# STM32G031 register map
File version: 1.6
CPU: CM0 r0p1, little endian, MPU, no FPU, 2 interrupt priority bits
Registers are 32-bit, read-write, reset 0x0 unless marked. A register's access mark holds for its fields unless they carry their own. Offsets are from the block's base; [hi:lo] are bit positions; lines under a group give offsets from that group; {n}, {i} and the like mark numbered series; 'fields as' and 'values as' point back to an identical list.

## ADC — Analog to Digital Converter instance 1
Base 0x40012400
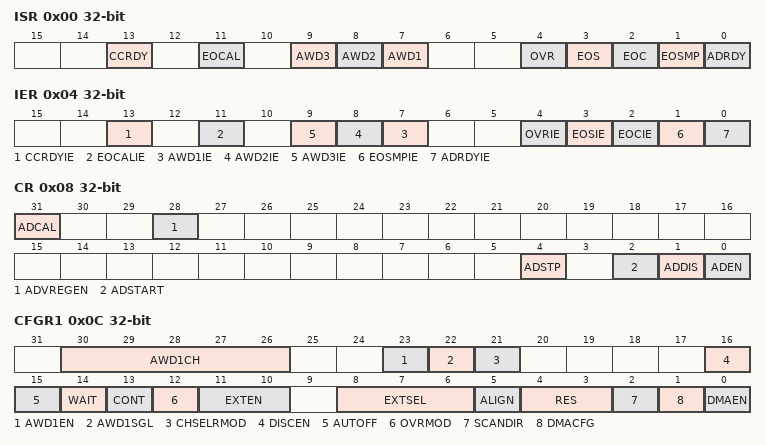
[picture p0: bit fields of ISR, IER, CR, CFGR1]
0x00 ISR — ADC interrupt and status register
  [13] CCRDY write-1-clears — Channel Configuration Ready flag
    on read: 0=NotComplete (Channel configuration update not applied); 1=Complete (Channel configuration update is applied) | on write: 1=Clear the channel configuration flag
  [11] EOCAL write-1-clears — End Of Calibration flag
    on read: 0=NotComplete (Calibration is not complete); 1=Complete (Calibration complete) | on write: 1=Clear the calibration flag
  [n+6] AWD{n} (n=1..3) write-1-clears — Analog watchdog {n} flag
    on read: 0=NoEvent (No analog watchdog event occurred); 1=Event (Analog watchdog event occurred) | on write: 1=Clear the analog watchdog event flag
  [4] OVR write-1-clears — ADC group regular overrun flag
    on read: 0=No overrun occurred; 1=Overrun occurred | on write: 1=Clear the overrun flag
  [3] EOS write-1-clears — ADC group regular end of sequence conversions flag
    on read: 0=NotComplete (Conversion sequence is not complete); 1=Complete (Conversion sequence complete) | on write: 1=Clear the conversion sequence flag
  [2] EOC write-1-clears — ADC group regular end of unitary conversion flag
    on read: 0=NotComplete (Channel conversion is not complete); 1=Complete (Channel conversion complete) | on write: 1=Clear the channel conversion flag
  [1] EOSMP write-1-clears — ADC group regular end of sampling flag
    on read: 0=NotAtEnd (Not at the end of the samplings phase); 1=AtEnd (End of sampling phase reached) | on write: 1=Clear the sampling phase flag
  [0] ADRDY write-1-clears — ADC ready flag
    on read: 0=NotReady (ADC not yet ready to start conversion); 1=Ready (ADC ready to start conversion) | on write: 1=Clear the ADC ready flag
0x04 IER — ADC interrupt enable register
  [13] CCRDYIE — Channel Configuration Ready Interrupt enable
    0=Disabled (Channel configuration ready interrupt disabled); 1=Enabled (Channel configuration ready interrupt enabled)
  [11] EOCALIE — End of calibration interrupt enable
    0=Disabled (End of calibration interrupt disabled); 1=Enabled (End of calibration interrupt enabled)
  [n+6] AWD{n}IE (n=1..3) — Analog watchdog {n} interrupt enable
    0=Disabled (Analog watchdog interrupt disabled); 1=Enabled (Analog watchdog interrupt enabled)
  [4] OVRIE — ADC group regular overrun interrupt
    0=Disabled (Overrun interrupt disabled); 1=Enabled (Overrun interrupt enabled. An interrupt is generated when the OVR bit is set.)
  [3] EOSIE — ADC group regular end of sequence conversions interrupt
    0=Disabled (EOS interrupt disabled); 1=Enabled (EOS interrupt enabled. An interrupt is generated when the EOS bit is set.)
  [2] EOCIE — ADC group regular end of unitary conversion interrupt
    0=Disabled (EOC interrupt disabled); 1=Enabled (EOC interrupt enabled. An interrupt is generated when the EOC bit is set.)
  [1] EOSMPIE — ADC group regular end of sampling interrupt
    0=Disabled (EOSMP interrupt disabled); 1=Enabled (EOSMP interrupt enabled. An interrupt is generated when the EOSMP bit is set.)
  [0] ADRDYIE — ADC ready interrupt
    0=Disabled (ADRDY interrupt disabled); 1=Enabled (ADRDY interrupt enabled. An interrupt is generated when the ADRDY bit is set.)
0x08 CR — ADC control register
  [31] ADCAL write-1-sets — ADC calibration
    on read: 0=NotCalibrating (ADC calibration either not yet performed or completed); 1=Calibrating (ADC calibration in progress) | on write: 1=StartCalibration (Start the ADC calibration sequence)
  [28] ADVREGEN — ADC voltage regulator enable
    0=Disabled (ADC voltage regulator disabled); 1=Enabled (ADC voltage regulator enabled)
  [4] ADSTP write-1-sets — ADC group regular conversion stop
    on read: 0=NotStopping (No stop command active); 1=Stopping (ADC stopping conversion) | on write: 1=StopConversion (Stop the active conversion)
  [2] ADSTART write-1-sets — ADC group regular conversion start
    on read: 0=NotActive (No conversion ongoing); 1=Active (ADC operating and may be converting) | on write: 1=StartConversion (Start the ADC conversion (may be delayed for hardware triggers))
  [1] ADDIS write-1-sets — ADC disable
    on read: 0=NotDisabling (No disable command active); 1=Disabling (ADC disabling) | on write: 1=Disable the ADC
  [0] ADEN write-1-sets — ADC enable
    on read: 0=Disabled (ADC disabled); 1=Enabled (ADC enabled) | on write: 1=Enabled (Enable the ADC)
0x0C CFGR1 — ADC configuration register 1
  [30:26] AWD1CH range 0..17 — ADC analog watchdog 1 monitored channel selection
  [23] AWD1EN — ADC analog watchdog 1 enable on scope ADC group regular
    0=Disabled (Analog watchdog 1 disabled); 1=Enabled (Analog watchdog 1 enabled)
  [22] AWD1SGL — ADC analog watchdog 1 monitoring a single channel or all channels
    0=AllChannels (Analog watchdog 1 enabled on all channels); 1=SingleChannel (Analog watchdog 1 enabled on a single channel)
  [21] CHSELRMOD — Mode selection of the ADC_CHSELR register
    0=BitPerInput (Each bit of the ADC_CHSELR register enables an input); 1=Sequence (ADC_CHSELR register is able to sequence up to 8 channels)
  [16] DISCEN — ADC group regular sequencer discontinuous mode
    0=Disabled (Discontinuous mode disabled); 1=Enabled (Discontinuous mode enabled)
  [15] AUTOFF — Auto-off mode
    0=Disabled (Auto-off mode disabled); 1=Enabled (Auto-off mode enabled)
  [14] WAIT — Wait conversion mode
    0=Disabled (Wait conversion mode off); 1=Enabled (Wait conversion mode on)
  [13] CONT — ADC group regular continuous conversion mode
    0=Single conversion mode; 1=Continuous conversion mode
  [12] OVRMOD — ADC group regular overrun configuration
    0=Preserve (ADC_DR register is preserved with the old data when an overrun is detected); 1=Overwrite (ADC_DR register is overwritten with the last conversion result when an overrun is detected)
  [11:10] EXTEN — ADC group regular external trigger polarity
    0=Disabled (Hardware trigger detection disabled); 1=RisingEdge (Hardware trigger detection on the rising edge); 2=FallingEdge (Hardware trigger detection on the falling edge); 3=BothEdges (Hardware trigger detection on both the rising and falling edges)
  [8:6] EXTSEL — ADC group regular external trigger source
    0=TIM1_TRGO2 (Timer 1 TRGO 2 event); 1=TIM1_CC4 (Timer 1 CC4 event); 2=TIM2_TRGO (Timer 2 TRGO event); 3=TIM3_TRGO (Timer 3 TRGO event); 4=TIM15_TRGO (Timer 15 TRGO event); 5=TIM6_TRGO (Timer 6 TRGO event); 6=TIM4_TRGO (Timer 4 TRGO event); 7=EXTI11 (EXTI line 11 event)
  [5] ALIGN — ADC data alignement
    0=Right alignment; 1=Left alignment
  [4:3] RES — ADC data resolution
    0=Bits12 (12 bits); 1=Bits10 (10 bits); 2=Bits8 (8 bits); 3=Bits6 (6 bits)
  [2] SCANDIR — Scan sequence direction
    0=Upward scan (from CHSEL0 to CHSEL17); 1=Backward scan (from CHSEL17 to CHSEL0)
  [1] DMACFG — ADC DMA transfer configuration
    0=OneShot (DMA one shot mode selected); 1=Circular (DMA circular mode selected)
  [0] DMAEN — ADC DMA transfer enable
    0=Disabled (DMA disabled); 1=Enabled (DMA enabled)
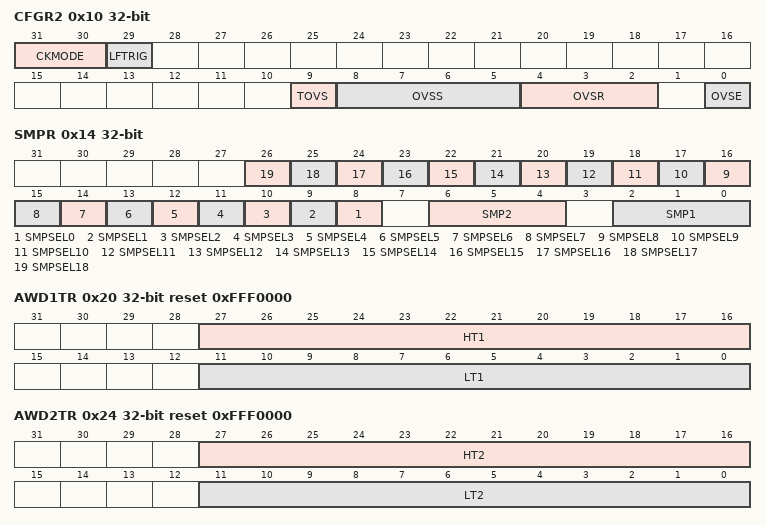
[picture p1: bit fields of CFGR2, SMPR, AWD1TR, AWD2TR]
0x10 CFGR2 — ADC configuration register 2
  [31:30] CKMODE — ADC clock mode
    0=ADCLK (ADCCLK (Asynchronous clock mode)); 1=PCLK_Div2 (PCLK/2 (Synchronous clock mode)); 2=PCLK_Div4 (PCLK/4 (Synchronous clock mode)); 3=PCLK (PCLK (Synchronous clock mode))
  [29] LFTRIG — Low frequency trigger mode enable
    0=Disabled (Low Frequency Trigger Mode disabled); 1=Enabled (Low Frequency Trigger Mode enabled)
  [9] TOVS — ADC oversampling discontinuous mode (triggered mode) for ADC group regular
    0=TriggerAll (All oversampled conversions for a channel are done consecutively after a trigger); 1=TriggerEach (Each oversampled conversion for a channel needs a trigger)
  [8:5] OVSS — ADC oversampling shift
    0=NoShift; 1=Shift 1-bit; {v}=Shift {v}-bits (v=2..8)
  [4:2] OVSR — ADC oversampling ratio
    0=Mul2 (2x); 1=Mul4 (4x); 2=Mul8 (8x); 3=Mul16 (16x); 4=Mul32 (32x); 5=Mul64 (64x); 6=Mul128 (128x); 7=Mul256 (256x)
  [0] OVSE — ADC oversampler enable on scope ADC group regular
    0=Disabled (Oversampler disabled); 1=Enabled (Oversampler enabled)
0x14 SMPR — ADC sampling time register
  [n+8] SMPSEL{n} (n=0..18) — Channel-{n} sampling time selection
    0=Smp1 (Sampling time of CHANNELx use the setting of SMP1 register); 1=Smp2 (Sampling time of CHANNELx use the setting of SMP2 register)
  [4n-2:4n-4] SMP{n} (n=1..2) — Sampling time selection {n}
    0=Cycles1_5 (1.5 ADC clock cycles); 1=Cycles3_5 (3.5 ADC clock cycles); 2=Cycles7_5 (7.5 ADC clock cycles); 3=Cycles12_5 (12.5 ADC clock cycles); 4=Cycles19_5 (19.5 ADC clock cycles); 5=Cycles39_5 (39.5 ADC clock cycles); 6=Cycles79_5 (79.5 ADC clock cycles); 7=Cycles160_5 (160.5 ADC clock cycles)
0x20 AWD1TR reset 0xFFF0000 — watchdog threshold register
  [27:16] HT1 — ADC analog watchdog 1 threshold high
  [11:0] LT1 — ADC analog watchdog 1 threshold low
0x24 AWD2TR reset 0xFFF0000 — watchdog threshold register
  [27:16] HT2 — ADC analog watchdog 2 threshold high
  [11:0] LT2 — ADC analog watchdog 2 threshold low
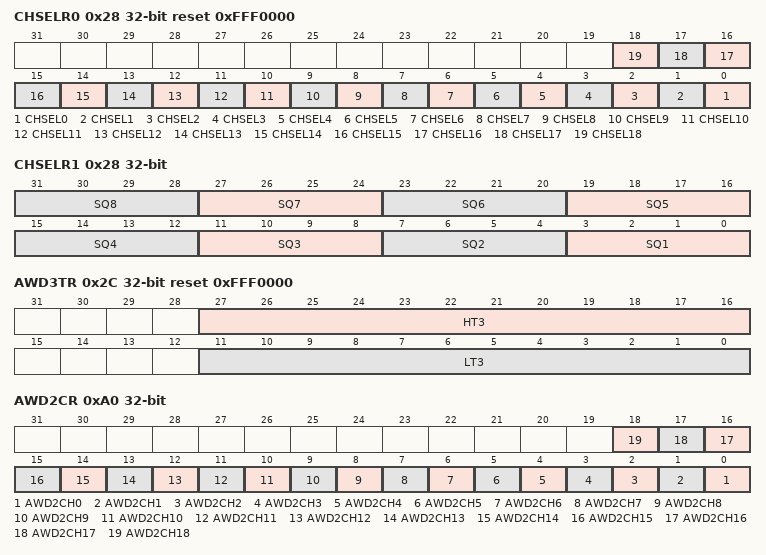
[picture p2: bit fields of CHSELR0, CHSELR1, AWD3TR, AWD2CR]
0x28 CHSELR0 reset 0xFFF0000 — channel selection register
  [n] CHSEL{n} (n=0..18) — Channel-{n} selection
    0=NotSelected (Input Channel is not selected for conversion); 1=Selected (Input Channel is selected for conversion)
0x28 CHSELR1 (alternate view of CHSELR0) — channel selection register CHSELRMOD = 1 in ADC_CFGR1
  [4n-1:4n-4] SQ{n} (n=1..8) — {n} conversion of the sequence
    {v}=Ch{v} (Channel {v} selected for the Nth conversion) (v=0..14); 15=EOS (End of sequence)
0x2C AWD3TR reset 0xFFF0000 — watchdog threshold register
  [27:16] HT3 — ADC analog watchdog 3 threshold high
  [11:0] LT3 — ADC analog watchdog 3 threshold high
0x40 DR ro — ADC group regular conversion data register
  [15:0] DATA — ADC group regular conversion data
0xA0 AWD2CR — ADC analog watchdog 2 configuration register
  [n] AWD2CH{n} (n=0..18) — ADC analog watchdog 2 monitored channel selection
    0=NotMonitored (ADC analog channel-x is not monitored by AWD2); 1=Monitored (ADC analog channel-x is monitored by AWD2)
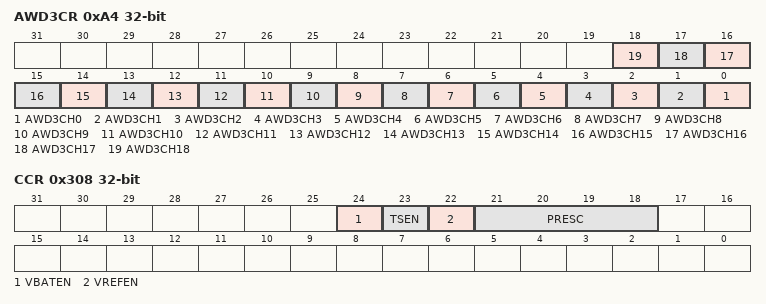
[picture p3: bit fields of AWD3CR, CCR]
0xA4 AWD3CR — ADC analog watchdog 3 configuration register
  [n] AWD3CH{n} (n=0..18) — ADC analog watchdog 3 monitored channel selection
    0=NotMonitored (ADC analog channel-x is not monitored by AWD3); 1=Monitored (ADC analog channel-x is monitored by AWD3)
0xB4 CALFACT — ADC calibration factors register
  [6:0] CALFACT — ADC calibration factor in single-ended mode
0x308 CCR — ADC common control register
  [24] VBATEN — VBAT enable
    0=Disabled (The selected ADC channel disabled); 1=Enabled (The selected ADC channel enabled)
  [23] TSEN — Temperature sensor enable
    values as VBATEN
  [22] VREFEN — VREFINT enable
    values as VBATEN
  [21:18] PRESC — ADC prescaler
    0=Div1 (Input ADC clock not divided); 1=Div2 (Input ADC clock divided by 2); 2=Div4 (Input ADC clock divided by 4); 3=Div6 (Input ADC clock divided by 6); 4=Div8 (Input ADC clock divided by 8); 5=Div10 (Input ADC clock divided by 10); 6=Div12 (Input ADC clock divided by 12); 7=Div16 (Input ADC clock divided by 16); 8=Div32 (Input ADC clock divided by 32); 9=Div64 (Input ADC clock divided by 64); 10=Div128 (Input ADC clock divided by 128); 11=Div256 (Input ADC clock divided by 256)
